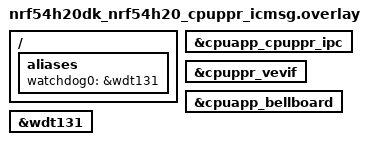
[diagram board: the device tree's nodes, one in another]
/*
 * Copyright (c) 2026 Nordic Semiconductor ASA
 *
 * SPDX-License-Identifier: Apache-2.0
 */

ipc0: &cpuapp_cpuppr_ipc {
	status = "okay";
};

&cpuppr_vevif {
	status = "okay";
};

&cpuapp_bellboard {
	status = "okay";
};

&wdt131 {
	status = "okay";
};

/ {
	aliases {
		watchdog0 = &wdt131;
	};
};
